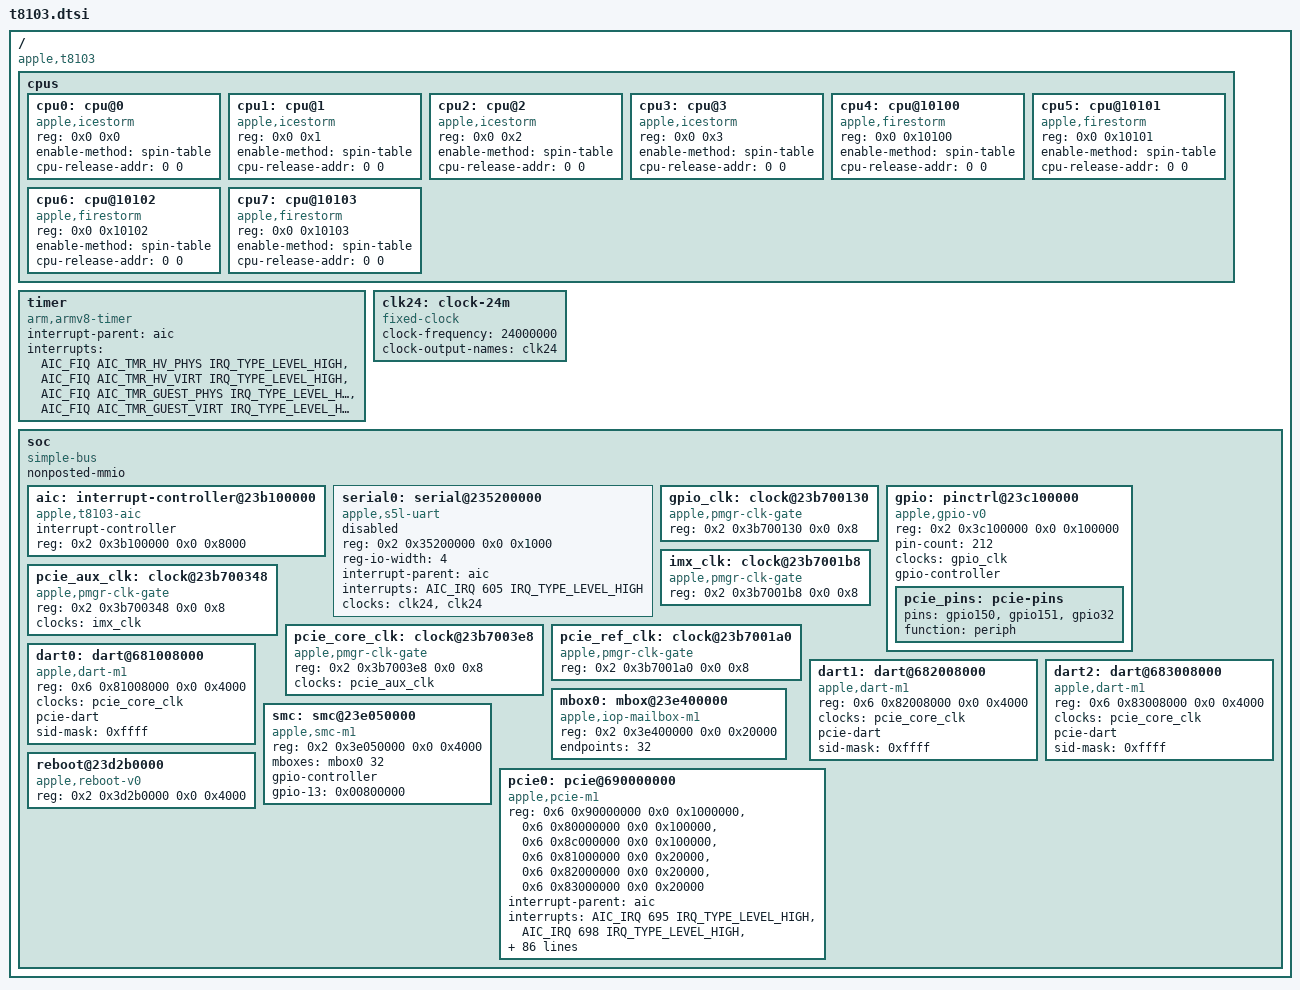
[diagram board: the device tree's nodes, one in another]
// SPDX-License-Identifier: GPL-2.0+ OR MIT
/*
 * Apple T8103 "M1" SoC
 *
 * Other names: H13G, "Tonga"
 *
 * Copyright The Asahi Linux Contributors
 */

#include <dt-bindings/interrupt-controller/apple-aic.h>
#include <dt-bindings/interrupt-controller/irq.h>

/ {
	compatible = "apple,t8103", "apple,arm-platform";

	#address-cells = <2>;
	#size-cells = <2>;

	cpus {
		#address-cells = <2>;
		#size-cells = <0>;

		cpu0: cpu@0 {
			compatible = "apple,icestorm";
			device_type = "cpu";
			reg = <0x0 0x0>;
			enable-method = "spin-table";
			cpu-release-addr = <0 0>; /* To be filled by loader */
		};

		cpu1: cpu@1 {
			compatible = "apple,icestorm";
			device_type = "cpu";
			reg = <0x0 0x1>;
			enable-method = "spin-table";
			cpu-release-addr = <0 0>; /* To be filled by loader */
		};

		cpu2: cpu@2 {
			compatible = "apple,icestorm";
			device_type = "cpu";
			reg = <0x0 0x2>;
			enable-method = "spin-table";
			cpu-release-addr = <0 0>; /* To be filled by loader */
		};

		cpu3: cpu@3 {
			compatible = "apple,icestorm";
			device_type = "cpu";
			reg = <0x0 0x3>;
			enable-method = "spin-table";
			cpu-release-addr = <0 0>; /* To be filled by loader */
		};

		cpu4: cpu@10100 {
			compatible = "apple,firestorm";
			device_type = "cpu";
			reg = <0x0 0x10100>;
			enable-method = "spin-table";
			cpu-release-addr = <0 0>; /* To be filled by loader */
		};

		cpu5: cpu@10101 {
			compatible = "apple,firestorm";
			device_type = "cpu";
			reg = <0x0 0x10101>;
			enable-method = "spin-table";
			cpu-release-addr = <0 0>; /* To be filled by loader */
		};

		cpu6: cpu@10102 {
			compatible = "apple,firestorm";
			device_type = "cpu";
			reg = <0x0 0x10102>;
			enable-method = "spin-table";
			cpu-release-addr = <0 0>; /* To be filled by loader */
		};

		cpu7: cpu@10103 {
			compatible = "apple,firestorm";
			device_type = "cpu";
			reg = <0x0 0x10103>;
			enable-method = "spin-table";
			cpu-release-addr = <0 0>; /* To be filled by loader */
		};
	};

	timer {
		compatible = "arm,armv8-timer";
		interrupt-parent = <&aic>;
		interrupt-names = "hyp-phys", "hyp-virt", "phys", "virt";
		interrupts = <AIC_FIQ AIC_TMR_HV_PHYS IRQ_TYPE_LEVEL_HIGH>,
			     <AIC_FIQ AIC_TMR_HV_VIRT IRQ_TYPE_LEVEL_HIGH>,
			     <AIC_FIQ AIC_TMR_GUEST_PHYS IRQ_TYPE_LEVEL_HIGH>,
			     <AIC_FIQ AIC_TMR_GUEST_VIRT IRQ_TYPE_LEVEL_HIGH>;
	};

	clk24: clock-24m {
		compatible = "fixed-clock";
		#clock-cells = <0>;
		clock-frequency = <24000000>;
		clock-output-names = "clk24";
	};

	soc {
		compatible = "simple-bus";
		#address-cells = <2>;
		#size-cells = <2>;

		ranges;
		nonposted-mmio;

		aic: interrupt-controller@23b100000 {
			compatible = "apple,t8103-aic", "apple,aic";
			#interrupt-cells = <3>;
			interrupt-controller;
			reg = <0x2 0x3b100000 0x0 0x8000>;
		};

		serial0: serial@235200000 {
			compatible = "apple,s5l-uart";
			reg = <0x2 0x35200000 0x0 0x1000>;
			reg-io-width = <4>;
			interrupt-parent = <&aic>;
			interrupts = <AIC_IRQ 605 IRQ_TYPE_LEVEL_HIGH>;
			/*
			 * TODO: figure out the clocking properly, there may
			 * be a third selectable clock.
			 */
			clocks = <&clk24>, <&clk24>;
			clock-names = "uart", "clk_uart_baud0";
			status = "disabled";
		};

		gpio_clk: clock@23b700130 {
			compatible = "apple,pmgr-clk-gate";
			reg = <0x2 0x3b700130 0x0 0x8>;
			#clock-cells = <0>;
		};

		gpio: pinctrl@23c100000 {
			compatible = "apple,gpio-v0";
			reg = <0x2 0x3c100000 0x0 0x100000>;
			pin-count = <212>;
			clocks = <&gpio_clk>;
			gpio-controller;
			#gpio-cells = <2>;

			pcie_pins: pcie-pins {
				pins = "gpio150", "gpio151", "gpio32";
				function = "periph";
			};
		};

		imx_clk: clock@23b7001b8 {
			compatible = "apple,pmgr-clk-gate";
			reg = <0x2 0x3b7001b8 0x0 0x8>;
			#clock-cells = <0>;
		};

		pcie_aux_clk: clock@23b700348 {
			compatible = "apple,pmgr-clk-gate";
			reg = <0x2 0x3b700348 0x0 0x8>;
			#clock-cells = <0>;
			clocks = <&imx_clk>;
		};

		pcie_core_clk: clock@23b7003e8 {
			compatible = "apple,pmgr-clk-gate";
			reg = <0x2 0x3b7003e8 0x0 0x8>;
			#clock-cells = <0>;
			clocks = <&pcie_aux_clk>;
		};

		pcie_ref_clk: clock@23b7001a0 {
			compatible = "apple,pmgr-clk-gate";
			reg = <0x2 0x3b7001a0 0x0 0x8>;
			#clock-cells = <0>;
		};

		dart0: dart@681008000 {
			compatible = "apple,dart-m1";
			reg = <0x6 0x81008000 0x0 0x4000>;
			#iommu-cells = <1>;
			clocks = <&pcie_core_clk>;
			pcie-dart;
			sid-mask = <0xffff>;
		};

		dart1: dart@682008000 {
			compatible = "apple,dart-m1";
			reg = <0x6 0x82008000 0x0 0x4000>;
			#iommu-cells = <1>;
			clocks = <&pcie_core_clk>;
			pcie-dart;
			sid-mask = <0xffff>;
		};

		dart2: dart@683008000 {
			compatible = "apple,dart-m1";
			reg = <0x6 0x83008000 0x0 0x4000>;
			#iommu-cells = <1>;
			clocks = <&pcie_core_clk>;
			pcie-dart;
			sid-mask = <0xffff>;
		};

		mbox0: mbox@23e400000 {
			compatible = "apple,iop-mailbox-m1";
			reg = <0x2 0x3e400000 0x0 0x20000>;
			#mbox-cells = <1>;
			endpoints = <32>;
		};

		smc: smc@23e050000 {
			compatible = "apple,smc-m1";
			reg = <0x2 0x3e050000 0x0 0x4000>;
			mboxes = <&mbox0 32>;
			gpio-controller;
			#gpio-cells = <2>;
			gpio-13 = <0x00800000>;
		};

		pcie0: pcie@690000000 {
			compatible = "apple,pcie-m1";
			reg = <0x6 0x90000000 0x0 0x1000000>,
			      <0x6 0x80000000 0x0 0x100000>,
			      <0x6 0x8c000000 0x0 0x100000>,
			      <0x6 0x81000000 0x0 0x20000>,
			      <0x6 0x82000000 0x0 0x20000>,
			      <0x6 0x83000000 0x0 0x20000>;
			interrupt-parent = <&aic>;
			interrupts = <AIC_IRQ 695 IRQ_TYPE_LEVEL_HIGH>,
				     <AIC_IRQ 698 IRQ_TYPE_LEVEL_HIGH>,
				     <AIC_IRQ 701 IRQ_TYPE_LEVEL_HIGH>,
				     <AIC_IRQ 704 IRQ_TYPE_LEVEL_HIGH>,
				     <AIC_IRQ 705 IRQ_TYPE_LEVEL_HIGH>,
				     <AIC_IRQ 706 IRQ_TYPE_LEVEL_HIGH>,
				     <AIC_IRQ 707 IRQ_TYPE_LEVEL_HIGH>,
				     <AIC_IRQ 708 IRQ_TYPE_LEVEL_HIGH>,
				     <AIC_IRQ 709 IRQ_TYPE_LEVEL_HIGH>,
				     <AIC_IRQ 710 IRQ_TYPE_LEVEL_HIGH>,
				     <AIC_IRQ 711 IRQ_TYPE_LEVEL_HIGH>,
				     <AIC_IRQ 712 IRQ_TYPE_LEVEL_HIGH>,
				     <AIC_IRQ 713 IRQ_TYPE_LEVEL_HIGH>,
				     <AIC_IRQ 714 IRQ_TYPE_LEVEL_HIGH>,
				     <AIC_IRQ 715 IRQ_TYPE_LEVEL_HIGH>,
				     <AIC_IRQ 716 IRQ_TYPE_LEVEL_HIGH>,
				     <AIC_IRQ 717 IRQ_TYPE_LEVEL_HIGH>,
				     <AIC_IRQ 718 IRQ_TYPE_LEVEL_HIGH>,
				     <AIC_IRQ 719 IRQ_TYPE_LEVEL_HIGH>,
				     <AIC_IRQ 720 IRQ_TYPE_LEVEL_HIGH>,
				     <AIC_IRQ 721 IRQ_TYPE_LEVEL_HIGH>,
				     <AIC_IRQ 722 IRQ_TYPE_LEVEL_HIGH>,
				     <AIC_IRQ 723 IRQ_TYPE_LEVEL_HIGH>,
				     <AIC_IRQ 724 IRQ_TYPE_LEVEL_HIGH>,
				     <AIC_IRQ 725 IRQ_TYPE_LEVEL_HIGH>,
				     <AIC_IRQ 726 IRQ_TYPE_LEVEL_HIGH>,
				     <AIC_IRQ 727 IRQ_TYPE_LEVEL_HIGH>,
				     <AIC_IRQ 728 IRQ_TYPE_LEVEL_HIGH>,
				     <AIC_IRQ 729 IRQ_TYPE_LEVEL_HIGH>,
				     <AIC_IRQ 730 IRQ_TYPE_LEVEL_HIGH>,
				     <AIC_IRQ 731 IRQ_TYPE_LEVEL_HIGH>,
				     <AIC_IRQ 732 IRQ_TYPE_LEVEL_HIGH>,
				     <AIC_IRQ 733 IRQ_TYPE_LEVEL_HIGH>,
				     <AIC_IRQ 734 IRQ_TYPE_LEVEL_HIGH>,
				     <AIC_IRQ 735 IRQ_TYPE_LEVEL_HIGH>;
			clocks = <&pcie_core_clk>, <&pcie_aux_clk>,
				 <&pcie_ref_clk>;
			iommu-map = <0x0 &dart0 0x8000 0x100>,
				    <0x100 &dart0 0x100 0x100>,
				    <0x200 &dart1 0x200 0x100>,
				    <0x300 &dart2 0x300 0x100>;
			iommu-map-mask = <0xff00>;
			msi-doorbell = <0x0 0xfffff000>;
			bus-range = <0 15>;
			#address-cells = <3>;
			#size-cells = <2>;
			ranges = <0x43000000 0x6 0xa0000000 0x6 0xa0000000
			          0x0 0x20000000>,
				 <0x02000000 0x0 0xc0000000 0x6 0xc0000000
				  0x0 0x40000000>;
			pinctrl-0 = <&pcie_pins>;
			pinctrl-names = "default";

			perst-gpios = <&gpio 152 0>, <&gpio 153 0>, <&gpio 33 0>;
			clkreq-gpios = <&gpio 150 0>, <&gpio 151 0>, <&gpio 32 0>;
			devpwr-gpios = <&smc 13 0>;
			devpwr-on-0 = <0 1>;
			devpwr-on-1;
			devpwr-on-2;

			refclk-always-on-2;
			max-speed-2 = <1>;

			device_type = "pci";

			tunable-axi2af = <0x20000000 0x00000003 0x00000000 0x20000038 0xffffffff 0x0000ffff 0x2000003c 0xffffffff 0x0000ffff 0x20000400 0x400103ff 0x40010001 0x20000600 0x01ffffff 0x01ffffff 0x20000738 0x01ff01ff 0x00200020 0x20000798 0x01ff01ff 0x00600010 0x20000800 0x00000100 0x00000100>;
			tunable-common = <0x1000002c 0x000000ff 0x00000001 0x10000054 0xffffffff 0x00000140>;

			tunable-phy-ip-auspma = <0x100ca10c 0x3fffffff 0x3fffffff 0x100cd024 0x000000ee 0x0000002c 0x100cb028 0x00000600 0x00000600 0x100cb02c 0x00000070 0x00000050 0x100cb038 0x03800000 0x03000000 0x100cb03c 0x07000000 0x07000000 0x100cb044 0xf0000000 0x70000000 0x100cb01c 0x07fc0fff 0x01c00c21 0x100cc008 0x0000fc00 0x00003800 0x100cc030 0x00003fc0 0x00002a00 0x100cc080 0x00f80000 0x00180000 0x100cc08c 0x0ffffff0 0x02222220 0x100c9014 0x00040000 0x00040000 0x100c902c 0x70000000 0x60000000 0x100c9040 0x00070000 0x00040000 0x100c9068 0x00000038 0x00000018 0x100c9074 0x0000003f 0x0000003e 0x100c90ac 0x001f8000 0x00040000 0x100c9104 0x0000ffff 0x00000202 0x100c9108 0x00000003 0x00000000 0x100c9110 0x0ffffff0 0x02222220 0x100c9000 0x40000000 0x00000000 0x100c9030 0xeeffff03 0x00ff0001 0x100cb028 0x00000600 0x00000600 0x100cb02c 0x00000070 0x00000050 0x100cb038 0x03800000 0x03000000 0x100cb03c 0x07000000 0x07000000 0x100cb044 0xf0000000 0x70000000 0x100cb01c 0x07fc0fff 0x01c00c21 0x100cb008 0x0007c01f 0x00060011 0x100cb084 0x00084210 0x00084210 0x100c9014 0x00040000 0x00040000 0x100c902c 0x70000000 0x60000000 0x100c9040 0x00070000 0x00040000 0x100c9068 0x00000038 0x00000018 0x100c9074 0x0000003f 0x0000003e 0x100c90ac 0x001f8000 0x00040000 0x100c9104 0x0000ffff 0x00000202 0x100c9108 0x00000003 0x00000000 0x100c9110 0x0ffffff0 0x02222220 0x100c9000 0x40000000 0x00000000 0x100c9030 0xeeffff03 0x00ff0001 0x100c9000 0x7e000000 0x58000000 0x100c9030 0xeeffff03 0xcc330c01 0x100c90e4 0x0fffffff 0x01a50694 0x100ca10c 0x3fffffff 0x3fffffff 0x100ca048 0x0000000f 0x00000002 0x100ca050 0x0000003c 0x0000003c 0x100ca054 0x0000000f 0x00000002 0x100ca05c 0x0000003c 0x0000003c 0x100ca07c 0x00000fff 0x000007ff 0x100ca08c 0x00000fff 0x00000fff 0x100ca094 0x000007ff 0x000003ff 0x100ca098 0x0000003f 0x0000003f 0x100ca0bc 0x0000000f 0x00000002 0x100ca0c4 0x7ff80000 0x05000000 0x100ca0d8 0x000fffff 0x0000c350 0x100d210c 0x3fffffff 0x3fffffff 0x100d5024 0x000000ee 0x0000002c 0x100d3028 0x00000600 0x00000600 0x100d302c 0x00000070 0x00000050 0x100d3038 0x03800000 0x03000000 0x100d303c 0x07000000 0x07000000 0x100d3044 0xf0000000 0x70000000 0x100d301c 0x07fc0fff 0x01c00c21 0x100d4008 0x0000fc00 0x00003800 0x100d4030 0x00003fc0 0x00002a00 0x100d4080 0x00f80000 0x00180000 0x100d408c 0x0ffffff0 0x02222220 0x100d1014 0x00040000 0x00040000 0x100d102c 0x70000000 0x60000000 0x100d1040 0x00070000 0x00040000 0x100d1068 0x00000038 0x00000018 0x100d1074 0x0000003f 0x0000003e 0x100d10ac 0x001f8000 0x00040000 0x100d1104 0x0000ffff 0x00000202 0x100d1108 0x00000003 0x00000000 0x100d1110 0x0ffffff0 0x02222220 0x100d1000 0x40000000 0x00000000 0x100d1030 0xeeffff03 0x00ff0001 0x100d3028 0x00000600 0x00000600 0x100d302c 0x00000070 0x00000050 0x100d3038 0x03800000 0x03000000 0x100d303c 0x07000000 0x07000000 0x100d3044 0xf0000000 0x70000000 0x100d301c 0x07fc0fff 0x01c00c21 0x100d3008 0x0007c01f 0x00070011 0x100d3084 0x00087e1f 0x00087211 0x100d1014 0x00040000 0x00040000 0x100d102c 0x70000000 0x60000000 0x100d1040 0x00070000 0x00040000 0x100d1068 0x00000038 0x00000018 0x100d1074 0x0000003f 0x0000003e 0x100d10ac 0x001f8000 0x00040000 0x100d1104 0x0000ffff 0x00000202 0x100d1108 0x00000003 0x00000000 0x100d1110 0x0ffffff0 0x02222220 0x100d1000 0x40000000 0x00000000 0x100d1030 0xeeffff03 0x00ff0001 0x100d1000 0x7e000000 0x58000000 0x100d1030 0xeeffff03 0xcc330c01 0x100d10e4 0x0fffffff 0x01a50694 0x100d210c 0x3fffffff 0x3fffffff 0x100d2048 0x0000000f 0x00000002 0x100d2050 0x0000003c 0x0000003c 0x100d2054 0x0000000f 0x00000002 0x100d205c 0x0000003c 0x0000003c 0x100d207c 0x00000fff 0x000007ff 0x100d208c 0x00000fff 0x00000fff 0x100d2094 0x000007ff 0x000003ff 0x100d2098 0x0000003f 0x0000003f 0x100d20bc 0x0000000f 0x00000002 0x100d20c4 0x7ff80000 0x05000000 0x100d20d8 0x000fffff 0x0000c350 0x100da10c 0x3fffffff 0x3fffffff 0x100dd024 0x000000ee 0x0000002c 0x100db028 0x00000600 0x00000600 0x100db02c 0x00000070 0x00000050 0x100db038 0x03800000 0x03000000 0x100db03c 0x07000000 0x07000000 0x100db044 0xf0000000 0x70000000 0x100db01c 0x07fc0fff 0x01c00c21 0x100dc008 0x0000fc00 0x00003800 0x100dc030 0x00003fc0 0x00002a00 0x100dc080 0x00f80000 0x00180000 0x100dc08c 0x0ffffff0 0x02222220 0x100d9014 0x00040000 0x00040000 0x100d902c 0x70000000 0x60000000 0x100d9040 0x00070000 0x00040000 0x100d9068 0x00000038 0x00000018 0x100d9074 0x0000003f 0x0000003e 0x100d90ac 0x001f8000 0x00040000 0x100d9104 0x0000ffff 0x00000202 0x100d9108 0x00000003 0x00000000 0x100d9110 0x0ffffff0 0x02222220 0x100d9000 0x40000000 0x00000000 0x100d9030 0xeeffff03 0x00ff0001 0x100db028 0x00000600 0x00000600 0x100db02c 0x00000070 0x00000050 0x100db038 0x03800000 0x03000000 0x100db03c 0x07000000 0x07000000 0x100db044 0xf0000000 0x70000000 0x100db01c 0x07fc0fff 0x01c00c21 0x100db008 0x0007c01f 0x00074011 0x100db084 0x000fffff 0x000ef631 0x100d9014 0x00040000 0x00040000 0x100d902c 0x70000000 0x60000000 0x100d9040 0x00070000 0x00040000 0x100d9068 0x00000038 0x00000018 0x100d9074 0x0000003f 0x0000003e 0x100d90ac 0x001f8000 0x00040000 0x100d9104 0x0000ffff 0x00000202 0x100d9108 0x00000003 0x00000000 0x100d9110 0x0ffffff0 0x02222220 0x100d9000 0x40000000 0x00000000 0x100d9030 0xeeffff03 0x00ff0001 0x100d9000 0x7e000000 0x58000000 0x100d9030 0xeeffff03 0xcc330c01 0x100d90e4 0x0fffffff 0x01a50694 0x100da10c 0x3fffffff 0x3fffffff 0x100da048 0x0000000f 0x00000002 0x100da050 0x0000003c 0x0000003c 0x100da054 0x0000000f 0x00000002 0x100da05c 0x0000003c 0x0000003c 0x100da07c 0x00000fff 0x000007ff 0x100da08c 0x00000fff 0x00000fff 0x100da094 0x000007ff 0x000003ff 0x100da098 0x0000003f 0x0000003f 0x100da0bc 0x0000000f 0x00000002 0x100da0c4 0x7ff80000 0x05000000 0x100da0d8 0x000fffff 0x0000c350>;

			tunable-phy-ip-pll = <0x100c002c 0x0001fe00 0x00009000 0x100c1200 0x0003fc00 0x0003c000 0x100c402c 0x003c0000 0x00040000 0x100c5080 0x3ffc0000 0x298c0000 0x100c5088 0x000f0000 0x00060000 0x100c508c 0x3ffc0000 0x298c0000 0x100c5094 0x000f0000 0x00060000 0x100c50a0 0x000f0000 0x00050000 0x100c50ac 0x000f0000 0x00050000 0x100c50b8 0x000f0000 0x00050000 0x100c5200 0x00000006 0x00000006 0x100c5220 0x00000007 0x00000000 0x100c5224 0x3fc00000 0x18000000 0x100c522c 0x00000900 0x00000900 0x100c5230 0x003e0000 0x00200000 0x100c5278 0x08000000 0x00000000 0x100c52a4 0x00000001 0x00000001 0x100c52bc 0x00ffffff 0x00078078 0x100c608c 0x3c3c0000 0x200c0000 0x100c6200 0x00000006 0x00000006 0x100c6214 0x00000001 0x00000000 0x100c621c 0x00007000 0x00000000 0x100c6220 0x00000007 0x00000001 0x100c6224 0x00000003 0x00000001 0x100c6228 0x00000010 0x00000010 0x100c6230 0x003e0000 0x00200000 0x100c62bc 0x00ffffff 0x00078078>;
			tunable-phy = <0x10080008 0x00000001 0x00000001 0x10084004 0x00000077 0x00000035 0x10088004 0x00000077 0x00000035 0x1008c004 0x00000077 0x00000035>;

			tunable-port0-config = <0x30000140 0x00000001 0x00000001 0x30000144 0x00ffffff 0x00253770 0x30000800 0x00ff0000 0x00100000>;
			tunable-port0-gen3-shadow = <0x00000154 0x00000f0f 0x00000404 0x00000890 0x03000000 0x00000000 0x000008a8 0x00ffff00 0x00001000>;
			tunable-port0-gen4-shadow = <0x00000178 0x000000ff 0x00000044 0x00000890 0x03000000 0x01000000 0x000008a8 0x00ffff00 0x00001000>;
			tunable-port0 = <0x00000194 0x00fbff00 0x00000000 0x000002a4 0x80000000 0x00000000 0x00000890 0x00000001 0x00000000 0x00000b80 0x3f7f3f3f 0x1d1f3220 0x00000b84 0x00003f3f 0x00003f3f 0x00000078 0x00007000 0x00000000>;

            		tunable-port1-config = <0x40000140 0x00000001 0x00000001 0x40000144 0x00ffffff 0x00253770 0x40000800 0x00ff0000 0x00100000>;
			tunable-port1-gen3-shadow = <0x00008154 0x00000f0f 0x00000404 0x00008890 0x03000000 0x00000000 0x000088a8 0x00ffff00 0x00001000>;
            		tunable-port1-gen4-shadow = <0x00008890 0x03000000 0x01000000 0x000088a8 0x00ffff00 0x00001000 0x00008178 0x000000ff 0x00000044>;
            		tunable-port1 = <0x00008194 0x00fbff00 0x00000000 0x000082a4 0x80000000 0x00000000 0x00008890 0x00000001 0x00000000 0x00008b80 0x3f7f3f3f 0x1d1f3220 0x00008b84 0x00003f3f 0x00003f3f 0x00008078 0x00007000 0x00000000>;
            		tunable-port2-config = <0x50000140 0x00000001 0x00000001 0x50000144 0x00ffffff 0x00253770 0x50000800 0x00ff0000 0x00100000>;
            		tunable-port2-gen3-shadow = <0x00010154 0x00000f0f 0x00000404 0x00010890 0x03000000 0x00000000 0x000108a8 0x00ffff00 0x00001000>;
            		tunable-port2-gen4-shadow = <0x00010178 0x000000ff 0x00000044 0x00010890 0x03000000 0x01000000 0x000108a8 0x00ffff00 0x00001000>;
            		tunable-port2 = <0x00010194 0x00fbff00 0x00000000 0x000102a4 0x80000000 0x00000000 0x00010890 0x00000001 0x00000000 0x00010b80 0x3f7f3f3f 0x1d1f3220 0x00010b84 0x00003f3f 0x00003f3f 0x00010078 0x00007000 0x00000000>;

	    		tunable-fuse = <0x100c6238 0x0000007f 0x00000020 0x100c6220 0x0001c000 0x00014000 0x100c62a4 0x00060000 0x00040000 0x100c522c 0x00000600 0x00000600 0x100c522c 0x00007000 0x00005000 0x100c5220 0x0001c000 0x00008000 0x100c52a4 0x00060000 0x00040000 0x100c522c 0x001f0000 0x00100000 0x100c5278 0x00700000 0x00000000 0x100c5018 0x00000004 0x00000000 0x100c1204 0x0000007c 0x00000044>;
		};

		reboot@23d2b0000 {
			compatible = "apple,reboot-v0";
			reg = <0x2 0x3d2b0000 0x0 0x4000>;
		};
	};
};
